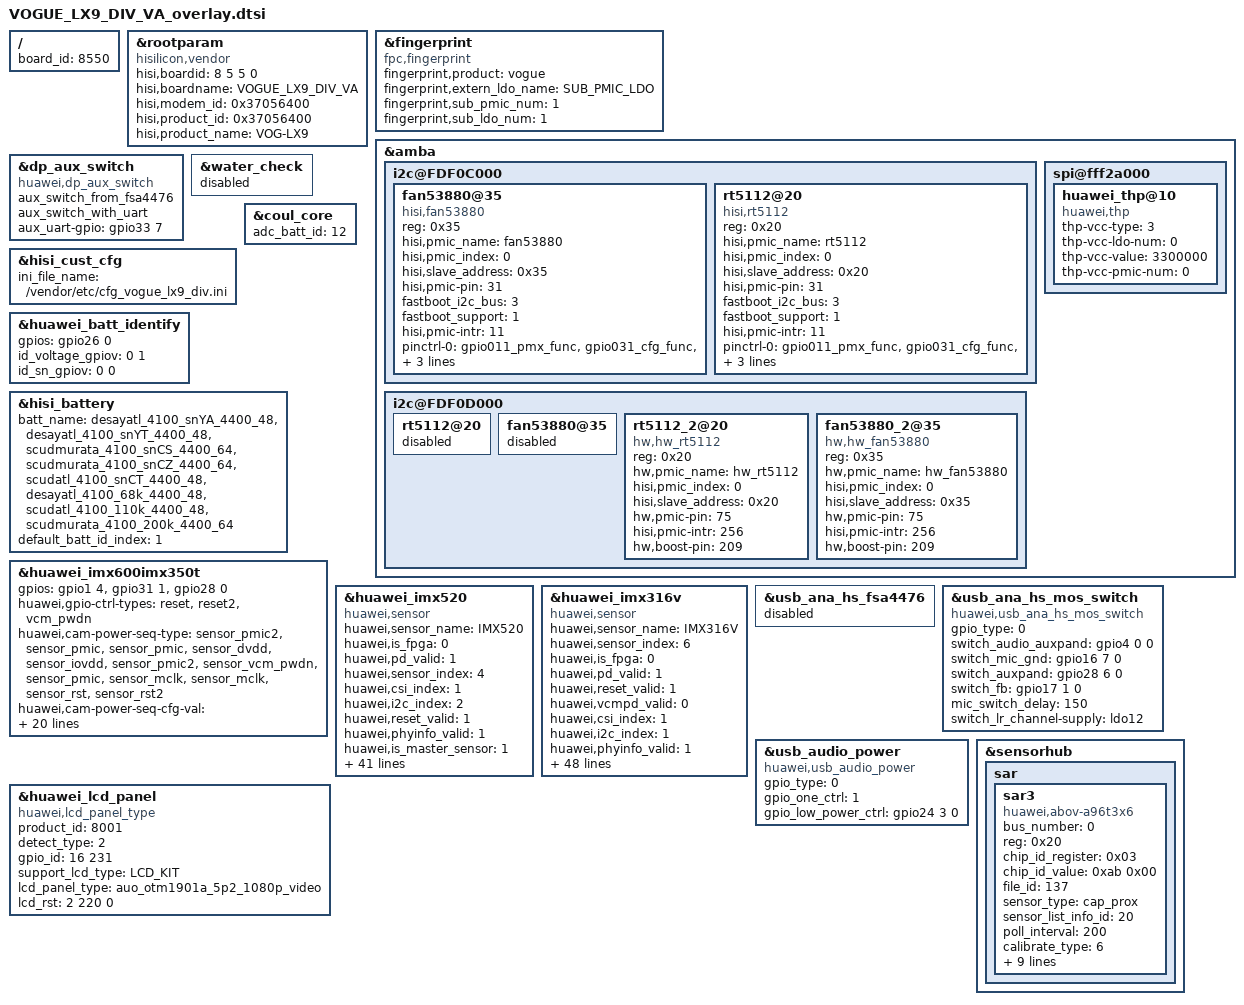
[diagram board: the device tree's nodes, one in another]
/**
 * Copyright (C) 2014 Hisilicon Ltd.
 *
 *  This program is free software; you can redistribute it and/or modify
 *  it under the terms of the GNU General Public License version 2 as
 *  publishhed by the Free Software Foundation.
 */

/include/ "desayatl_4100_68k_4400_48.dtsi"
/include/ "scudatl_4100_110k_4400_48.dtsi"
/include/ "scudmurata_4100_200k_4400_64.dtsi"
/include/ "desayatl_4100_snYA_4400_48.dtsi"
/include/ "desayatl_4100_snYT_4400_48.dtsi"
/include/ "scudmurata_4100_snCS_4400_64.dtsi"
/include/ "scudmurata_4100_snCZ_4400_64.dtsi"
/include/ "scudatl_4100_snCT_4400_48.dtsi"
/include/ "VOGUE_LX9_VE_overlay.dtsi"

/ {
    board_id = <8550>;
};
    &rootparam{
		compatible = "hisilicon,vendor";
		hisi,boardid = <8 5 5 0>;
		hisi,boardname = "VOGUE_LX9_DIV_VA";
		hisi,modem_id = <0x37056400>;
		hisi,product_id = <0x37056400>;
		hisi,product_name = "VOG-LX9";
	};

	&fingerprint {
		compatible = "fpc,fingerprint";
		fingerprint,product = "vogue";

		fingerprint,extern_ldo_name = "SUB_PMIC_LDO";
		fingerprint,sub_pmic_num = <1>;
		fingerprint,sub_ldo_num = <1>;
		/delete-property/ fingerprint,power_en_gpio;
		/delete-property/ fingreprint_ldo-supply;
		/delete-property/ fingerprint,extern_vol;
	};

	&amba {
		i2c@FDF0C000 {
			status = "ok";
			fan53880@35 {
				compatible = "hisi,fan53880";
				reg = <0x35>;
				hisi,pmic_name = "fan53880";
				hisi,pmic_index = <0>;
				hisi,slave_address = <0x35>;
				hisi,pmic-pin = <31>;
				fastboot_i2c_bus = <3>;
				fastboot_support = <1>;
				hisi,pmic-intr = <11>;
				pinctrl-names = "default", "idle";
				pinctrl-0 = <&gpio011_pmx_func &gpio031_cfg_func &gpio011_cfg_func &gpio031_cfg_func>;
				pinctrl-1 = <&gpio011_pmx_idle &gpio031_cfg_idle &gpio011_cfg_idle &gpio031_cfg_idle>;
				status = "ok";
			};
			rt5112@20 {
				compatible = "hisi,rt5112";
				reg = <0x20>;
				hisi,pmic_name = "rt5112";
				hisi,pmic_index = <0>;
				hisi,slave_address = <0x20>;
				hisi,pmic-pin = <31>;
				fastboot_i2c_bus = <3>;
				fastboot_support = <1>;
				hisi,pmic-intr = <11>;
				pinctrl-names = "default", "idle";
				pinctrl-0 = <&gpio011_pmx_func &gpio031_cfg_func &gpio011_cfg_func &gpio031_cfg_func>;
				pinctrl-1 = <&gpio011_pmx_idle &gpio031_cfg_idle &gpio011_cfg_idle &gpio031_cfg_idle>;
				status = "ok";
			};
		};
		i2c@FDF0D000 {
			rt5112@20 {
				status = "disabled";
			};
			fan53880@35 {
				status = "disabled";
			};
			rt5112_2@20 {
				compatible = "hw,hw_rt5112";
				reg = <0x20>;
				hw,pmic_name = "hw_rt5112";
				hisi,pmic_index = <0>;
				hisi,slave_address = <0x20>;
				hw,pmic-pin = <75>;
				hisi,pmic-intr = <256>;
				hw,boost-pin = <209>;
				status = "ok";
			};
			fan53880_2@35 {
				compatible = "hw,hw_fan53880";
				reg = <0x35>;
				hw,pmic_name = "hw_fan53880";
				hisi,pmic_index = <0>;
				hisi,slave_address = <0x35>;
				hw,pmic-pin = <75>;
				hisi,pmic-intr = <256>;
				hw,boost-pin = <209>;
				status = "ok";
			};
		};
		spi@fff2a000 { /* SPI3 */
			huawei_thp@10 {
				compatible = "huawei,thp";
				thp-vcc-type = <3>;    /* 0-unsued 1-ldo 2-gpio 3-pmic */
				thp-vcc-ldo-num = <0>; /* 0:VOUT_LDO_1 */
				thp-vcc-value = <3300000>;
				thp-vcc-pmic-num = <0>;
			};
		};
	};
	&dp_aux_switch {
		compatible = "huawei,dp_aux_switch";
		aux_switch_from_fsa4476;
		aux_switch_with_uart;
		aux_uart-gpio = <&gpio33 7 0>;
	};
	&water_check {
		status = "disabled";
	};

	/*hisi customize*/
	&hisi_cust_cfg {
		ini_file_name = "/vendor/etc/cfg_vogue_lx9_div.ini";
	};
	&huawei_batt_identify {
		gpios = <&gpio26 0 0>;
		id_voltage_gpiov = <0 1>;
		id_sn_gpiov = <0 0>;
		status = "ok";
	};
	&coul_core {
		adc_batt_id = <12>;
	};
	&hisi_battery {
		batt_name = <&desayatl_4100_snYA_4400_48 &desayatl_4100_snYT_4400_48 &scudmurata_4100_snCS_4400_64 &scudmurata_4100_snCZ_4400_64 &scudatl_4100_snCT_4400_48 &desayatl_4100_68k_4400_48 &scudatl_4100_110k_4400_48 &scudmurata_4100_200k_4400_64>;
		default_batt_id_index = <1>;
	};
	&huawei_imx600imx350t {
		/*lx9_vD delete gpio250*/
		gpios = <&gpio1 4 0 &gpio31 1 0 &gpio28 0 0>;
		huawei,gpio-ctrl-types = "reset", "reset2", "vcm_pwdn";

		huawei,cam-power-seq-type = "sensor_pmic2", "sensor_pmic", "sensor_pmic",
		"sensor_dvdd", "sensor_iovdd", "sensor_pmic2", "sensor_vcm_pwdn", "sensor_pmic",
		"sensor_mclk", "sensor_mclk",
		"sensor_rst", "sensor_rst2";
		huawei,cam-power-seq-cfg-val = <2800000 2800000 1800000 1100000 1800000 2850000 0 3100000 0 0 0 0>;
		huawei,cam-power-seq-val = <0 1 2 0xFF 0xFF 2 0xFF 5 0xFF 0xFF 0xFF 0xFF>;
		huawei,cam-power-seq-sensor-index = <0xFF 0xFF 0xFF 0xFF 0xFF 0xFF 0xFF 0xFF 0 2 0xFF 0xFF>;
		huawei,cam-power-seq-delay = <0 0 0 0 1 0 1 0 1 1 1 1>;

		huawei,cam-power-down-seq-type ="sensor_rst2", "sensor_rst", "sensor_mclk", "sensor_mclk", "sensor_pmic",
		"sensor_vcm_pwdn", "sensor_pmic2", "sensor_iovdd", "sensor_dvdd",
		"sensor_pmic", "sensor_pmic", "sensor_pmic";
		huawei,cam-power-down-seq-cfg-val = <0 0 0 0 3100000 0 2850000 1800000 1100000 1800000 2800000 2800000>;
		huawei,cam-power-down-seq-val = <0xFF 0xFF 0xFF 0xFF 5 0xFF 2 0xFF 0xFF 2 1 0>;
		huawei,cam-power-down-seq-sensor-index = <0xFF 0xFF 2 0 0xFF 0xFF 0xFF 0xFF 0xFF 0xFF 0xFF 0xFF>;
		huawei,cam-power-down-seq-delay = <1 1 1 1 0 1 0 1 0 0 0 0>;
		status = "ok";
	};

	&huawei_imx520 {
		compatible = "huawei,sensor";
		huawei,sensor_name = "IMX520";
		huawei,is_fpga = <0>;
		huawei,pd_valid = <1>;
		huawei,sensor_index = <4>;
		huawei,csi_index = <1>;
		huawei,i2c_index = <2>;
		huawei,reset_valid = <1>;
		/*cdphy-csi2*/
		huawei,phyinfo_valid = <1>;
		huawei,is_master_sensor = <1>;
		huawei,phy_id = <3>;
		huawei,phy_mode = <0>;
		huawei,phy_freq_mode = <0>;
		huawei,phy_freq = <80000000>;
		huawei,phy_work_mode = <0>;
		clock-names = "clk_rxdphy0_cfg", "clk_rxdphy1_cfg", "clk_rxdphy2_cfg", "clk_rxdphy3_cfg", "clk_isp_snclk2";
		clocks = <&clk_gate_rxdphy0_cfg &clk_gate_rxdphy1_cfg &clk_gate_rxdphy2_cfg &clk_gate_rxdphy3_cfg &clk_gate_isp_snclk2 >;
		huawei,mclk = <19200000>;
		huawei,rxdphyclk = <80000000>;
		huawei,phyclk = <80000000>;
		phy-clock-num = <4>;
		huawei,vcmpd_valid = <0>;
		dvdd-supply = <&ldo32>;
		iovdd-supply = <&ldo21>;
		huawei,ldo-names = "dvdd", "iovdd";

		gpios = <&gpio1 6 0 &gpio27 5 0 &gpio32 1 0>;
		huawei,gpio-ctrl-types = "reset", "mipisw", "fsin";//fsin:fpc check arg


		/*AFVDD buck2 2.85v| OIS LDO4 2.8V| AVDD LDO3 2.8V | DVDD	GPIO196 |
		 * IOVDD LDO20*/
		huawei,cam-power-seq-type = "sensor_pmic", "sensor_pmic2", "sensor_dvdd", "sensor_pmic",
		"sensor_iovdd","sensor_mipi_sw", "sensor_pmic2","sensor_mclk", "sensor_rst";
		huawei,cam-power-seq-cfg-val = <2800000 2850000 1100000 3100000 1800000 1 2850000 0 0>;
		huawei,cam-power-seq-val = <1 2 0xFF 5 0xFF 0xFF 3 0xFF 0xFF>;
		huawei,cam-power-seq-sensor-index = <0xFF 0xFF 0xFF 0xFF 0xFF 0xFF 0xFF 2 0xFF>;
		huawei,cam-power-seq-delay = <0 0 1 0 0 1 1 1 1>;

		huawei,cam-power-down-seq-type ="sensor_rst", "sensor_mclk","sensor_pmic2","sensor_mipi_sw",
		"sensor_iovdd", "sensor_pmic", "sensor_dvdd", "sensor_pmic2", "sensor_pmic";
		huawei,cam-power-down-seq-cfg-val = <0 0 2850000 1 1800000 3100000 1100000 2850000 2800000>;
		huawei,cam-power-down-seq-val = <0xFF 0xFF 3 0xFF 0xFF 5 0xFF 2 1>;
		huawei,cam-power-down-seq-sensor-index = <0xFF 2 0xFF 0xFF 0xFF 0xFF 0xFF 0xFF 0xFF>;
		huawei,cam-power-down-seq-delay = <1 1 1 1 0 0 1 0 0>;

		status = "ok";
	};

	&huawei_imx316v{
		compatible = "huawei,sensor";
		huawei,sensor_name = "IMX316V";
		huawei,sensor_index = <6>;/*2 moca*/
		huawei,is_fpga = <0>;
		huawei,pd_valid = <1>;
		huawei,reset_valid = <1>;
		huawei,vcmpd_valid = <0>;
		huawei,csi_index = <1>;
		huawei,i2c_index = <1>;
		/*cdphy-csi2*/
		huawei,phyinfo_valid = <1>;
		huawei,is_master_sensor = <1>;
		huawei,phy_id = <3>;
		huawei,phy_mode = <0>;
		huawei,phy_freq_mode = <0>;
		huawei,phy_freq = <80000000>;
		huawei,phy_work_mode = <0>;//dphy use single
		clock-names = "clk_rxdphy3_cfg";
		clocks = <&clk_gate_rxdphy3_cfg>;
		huawei,mclk = <24000000>;
		huawei,rxdphyclk = <80000000>;
		huawei,phyclk = <80000000>;
		phy-clock-num = <1>;
		iovdd-supply = <&ldo21>;
		dvdd-supply = <&ldo38>;
		huawei,ldo-names = "iovdd", "dvdd";
		gpios = <&gpio27 5 0 &gpio28 0 0 &gpio23 2 0 &gpio6 2 0>;
		huawei,gpio-ctrl-types = "mipisw", "dvdd1-en", "vcm_pwdn", "reset";
		huawei,cam-power-seq-type =
			"sensor_pmic2",
			"sensor_iovdd",
			"sensor_mipi_sw",
			"sensor_dvdd",
			"sensor_dvdd1_en",
			"sensor_vcm_pwdn",
			"sensor_mclk",
			"sensor_rst";
		huawei,cam-power-seq-cfg-val = <2850000 1800000 0 1205000 0 0 0 0>;
		huawei,cam-power-seq-val = <3 0xFF 0xFF 0xFF 0xFF 0xFF 0xFF 0xFF>;
		huawei,cam-power-seq-sensor-index = <0xFF 0xFF 0xFF 0xFF 0xFF 0xFF 6 0xFF>;
		huawei,cam-power-seq-delay = <1 0 1 0 1 1 0 1>;

		huawei,cam-power-down-seq-type =
			"sensor_rst",
			"sensor_mclk",
			"sensor_vcm_pwdn",
			"sensor_dvdd1_en",
			"sensor_dvdd",
			"sensor_mipi_sw",
			"sensor_iovdd",
			"sensor_pmic2";
		huawei,cam-power-down-seq-cfg-val = <0 0 0 0 1205000 0 1800000 2850000>;
		huawei,cam-power-down-seq-val = <0xFF 0xFF 0xFF 0xFF 0xFF 0xFF 0xFF 3>;
		huawei,cam-power-down-seq-sensor-index = <0xFF 6 0xFF 0xFF 0xFF 0xFF 0xFF 0xFF>;
		huawei,cam-power-down-seq-delay = <1 0 1 1 0 1 0 1>;

		huawei,ext_type = <2>;
		huawei,ext_name = "oflim_lumentum_no_coating", "sunny_lumentum_no_coating", "ofilm_vertilite_no_coating", "sunny_ams_no_coating";

		huawei,adc_threshold = <1900 1700 1000 800 700 500 500 350>;
		huawei,adc_channel = <9>;/*add for TOF Tx*/
		status = "ok";
	};

	&usb_ana_hs_fsa4476 {
		status = "disabled";
	};

	&usb_ana_hs_mos_switch {
		compatible = "huawei,usb_ana_hs_mos_switch";
		gpio_type = <0>;
		switch_audio_auxpand = <&gpio4 0 0>;
		switch_mic_gnd = <&gpio16 7 0>;
		switch_auxpand = <&gpio28 6 0>;
		switch_fb = <&gpio17 1 0>;
		mic_switch_delay = <150>;
		switch_lr_channel-supply = <&ldo12>;
		status = "ok";
	};

	&usb_audio_power {
		compatible = "huawei,usb_audio_power";
		gpio_type = <0>;
		gpio_one_ctrl = <1>;
		gpio_low_power_ctrl = <&gpio24 3 0>;
		status = "ok";
	};
	&sensorhub {
		sar{
			sar3 {
				compatible="huawei,abov-a96t3x6";
				bus_number=<0>;
				reg=<0x20>;
				chip_id_register=<0x03>;
				chip_id_value=<0xab 0x00>;
				file_id=<137>;
				sensor_type="cap_prox";
				sensor_list_info_id=<20>;
				poll_interval=<200>;
				calibrate_type=<6>; // bit config 101(b) adapt to the param calibrate calibrate order
				calibrate_order = "999 2 1"; // 0:free  1:near  2:far  3:other
				shared_flag=<0>;
				gpio_int=<&gpio27 6 0>;
				gpio_int_sh=<1023>;
				status = "ok";
				phone_type = /bits/ 16 <0x04>; // 1:VERDI 2:SCM 3:ELLE 4:VOGUE
				ph = <0x5>;
				calibrate_thred = /bits/ 16 <0 0 0 0>; // for the factory far and near calibrate
				sensorlist_name="CAP_PROX sensor-a96t3x6";
				vendor="abov";
			};
		};
	};

	&huawei_lcd_panel {
		compatible = "huawei,lcd_panel_type";
		product_id = <8001>;
		detect_type = <2>; /*0:DETECT_GPIOID  1:DETECT_CHIPID  2:DETECT_LCD_TYPE */
		gpio_id = <16 231>; /*ID0 ID1*/
		support_lcd_type = "LCD_KIT";
		lcd_panel_type = "auo_otm1901a_5p2_1080p_video";
		lcd_rst = <2 220 0>;
	};

